# apollo1 register map
Vendor: Ambiq Micro; Series: Apollo; File version: 1.0
CPU: CM4 r1p0, little endian, MPU, FPU, 3 interrupt priority bits
Registers are 32-bit, read-write, reset 0x0 unless marked. A register's access mark holds for its fields unless they carry their own. Offsets are from the block's base; [hi:lo] are bit positions; {n}, {i} and the like mark numbered series; 'fields as' and 'values as' point back to an identical list; <NAME> marks a mode.

## ADC — Analog Digital Converter Control
Base 0x50008000
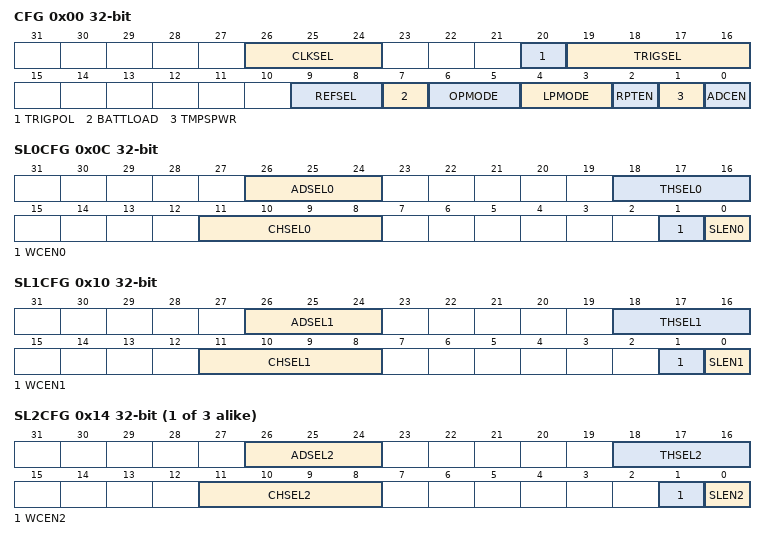
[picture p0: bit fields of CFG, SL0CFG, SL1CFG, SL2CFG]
0x00 CFG — Configuration Register
  [26:24] CLKSEL — Select the source and frequency for the ADC clock. All values not enumerated below are undefined.
    0=OFF (Low Power Mode. value.); 1=12MHZ (12 MHz ADC clock. value.); 2=6MHZ (6 MHz ADC clock. value.); 3=3MHZ (12 MHz ADC clock. value.); 4=1_5MHZ (1.5 MHz ADC clock. value.)
  [20] TRIGPOL — This bit selects the ADC trigger polarity for external off chip triggers.
    0=RISING_EDGE (Trigger on rising edge. value.); 1=FALLING_EDGE (Trigger on falling edge. value.)
  [19:16] TRIGSEL — Select the ADC trigger source.
    {v}=EXT{v} (Off chip External Trigger{v} (ADC_ET{v}) value.) (v=0..7); 8=SWT (Software Trigger value.)
  [9:8] REFSEL — Select the ADC reference voltage.
    0=INTERNAL (Internal Bandgap Reference Voltage value.); 1=VDD (Select VDD as the ADEC reference voltage. value.); 2=ADCREF (Off Chip Reference (ADC_REF) value.); 3=UNDEFINED (Reserved value.)
  [7] BATTLOAD — Control 500 Ohm battery load resistor.
    0=DIS (Disable battery load. value.); 1=EN (Enable battery load. value.)
  [6:5] OPMODE — Select the sample rate mode. It adjusts the current in the ADC for higher sample rates. A 12MHz ADC clock can result in a sample rate up to 1Msps depending on the trigger or repeating mode rate. A 1.5MHz ADC clock can result in a sample rate up 125K sps. NOTE: All other values not specified below are undefined.
    0=SAMPLE_RATE_LE_125KSPS (Sample Rate <= 125K sps value.); 2=SAMPLE_RATE_125K_1MSPS (Sample Rate 125K to 1M sps value.)
  [4:3] LPMODE — Select power mode to enter between active scans.
    0=MODE0 (Low Power Mode 0 (2'b00). Leaves the ADC fully powered between scans with no latency between a trigger event and sample data collection. value.); 1=MODE1 (Low Power Mode 1 (2'b01). Enables a low power mode for the ADC between scans requiring 50us initialization time (latency) between a trigger event and the scan (assuming the HFRC remains running and the MCU is not in deepsleep mode in which case additional startup latency for HFRC startup is required). value.); 2=MODE2 (Low Power Mode 2 (2'b10). Disconnects power and clocks to the ADC effectively eliminating all active power associated with the ADC between scans. This mode requires 150us initialization (again, assuming the HFRC remains running and the MCU is not in deepsleep mode in which case additional startup latency for HFRC startup is required). value.); 3=MODE_UNDEFINED (Undefined Mode (2'b11) value.)
  [2] RPTEN — This bit enables Repeating Scan Mode.
    0=SINGLE_SCAN (In Single Scan Mode, the ADC will complete a single scan upon each trigger event. value.); 1=REPEATING_SCAN (In Repeating Scan Mode, the ADC will complete it's first scan upon the initial trigger event and all subsequent scans will occur at regular intervals defined by the configuration programmed for the CTTMRA3 internal timer until the timer is disabled or the ADC is disabled. value.)
  [1] TMPSPWR — This enables power to the temperature sensor module. After setting this bit, the temperature sensor will remain powered down while the ADC is power is disconnected (i.e, when the ADC PWDSTAT is 2'b10).
    0=DIS (Power down the temperature sensor. value.); 1=EN (Enable the temperature sensor when the ADC is in it's active state. value.)
  [0] ADCEN — This bit enables the ADC module. While the ADC is enabled, the ADCCFG and SLOT Configuration regsiter settings must remain stable and unchanged.
    0=DIS (Disable the ADC module. value.); 1=EN (Enable the ADC module. value.)
0x04 STAT — ADC Power Status
  [1:0] PWDSTAT — Indicates the power-status of the ADC.
    0=ON (Powered on. value.); 1=SWITCH_ON_SAR_OFF (Power switch on, ADC Low Power Mode 1. value.); 2=POWER_SWITCH_OFF (Power switch off, ADC disabled. value.)
0x08 SWT — Software trigger
  [7:0] SWT — Writing 0x37 to this register generates a software trigger.
    55=GEN_SW_TRIGGER (Writing this value generates a software trigger. value.)
0x0C SL0CFG — Slot 0 Configuration Register
  [26:24] ADSEL0 — Select the number of measurements to average in the accumulate divide module for this slot.
    0=AVG_1_MSRMT (Average in 1 measurement in the accumulate divide module for this slot. value.); 1=AVG_2_MSRMTS (Average in 2 measurements in the accumulate divide module for this slot. value.); 2=AVG_4_MSRMTS (Average in 4 measurements in the accumulate divide module for this slot. value.); 3=AVG_8_MSRMT (Average in 8 measurements in the accumulate divide module for this slot. value.); 4=AVG_16_MSRMTS (Average in 16 measurements in the accumulate divide module for this slot. value.); 5=AVG_32_MSRMTS (Average in 32 measurements in the accumulate divide module for this slot. value.); 6=AVG_64_MSRMTS (Average in 64 measurements in the accumulate divide module for this slot. value.); 7=AVG_128_MSRMTS (Average in 128 measurements in the accumulate divide module for this slot. value.)
  [18:16] THSEL0 — Select the track and hold delay for this slot. NOTE: The track and hold delay must be less than 50us for correct operation. When the ADC is configured to use the 1.5Mhz clock, the track and hold delay cannot exceed 64 clocks.
    0=1_ADC_CLK (1 ADC clock cycle. value.); 1=2_ADC_CLKS (2 ADC clock cycles. value.); 2=4_ADC_CLKS (4 ADC clock cycles. value.); 3=8_ADC_CLKS (8 ADC clock cycles. value.); 4=16_ADC_CLKS (16 ADC clock cycles. value.); 5=32_ADC_CLKS (32 ADC clock cycles. value.); 6=64_ADC_CLKS (64 ADC clock cycles. value.); 7=128_ADC_CLKS (128 ADC clock cycles. value.)
  [11:8] CHSEL0 — Select one of the 13 channel inputs for this slot.
    {v}=EXT{v} (ADC_EXT{v} external GPIO pin connection. value.) (v=0..7); 8=TEMP (ADC_TEMP internal temperature sensor. value.); 9=VDD (ADC_VDD internal power rail connection. value.); 10=VSS (ADC_VSS internal ground connection. value.); 12=VBATT (ADC_VBATT internal voltage divide-by-3 connection to input power rail. value.)
  [1] WCEN0 — This bit enables the window compare function for slot 0.
    1=WCEN (Enable the window compare for slot 0. value.)
  [0] SLEN0 — This bit enables slot 0 for ADC conversions.
    1=SLEN (Enable slot 0 for ADC conversions. value.)
0x10 SL1CFG — Slot 1 Configuration Register
  [26:24] ADSEL1 — Select the number of measurements to average in the accumulate divide module for this slot.
    values as SL0CFG.ADSEL0
  [18:16] THSEL1 — Select the track and hold delay for this slot. NOTE: The track and hold delay must be less than 50us for correct operation. When the ADC is configured to use the 1.5 Mhz clock, the track and hold delay cannot exceed 64 clocks.
    values as SL0CFG.THSEL0
  [11:8] CHSEL1 — Select one of the 13 channel inputs for this slot.
    values as SL0CFG.CHSEL0
  [1] WCEN1 — This bit enables the window compare function for slot 1.
    1=WCEN (Enable the window compare for slot 1. value.)
  [0] SLEN1 — This bit enables slot 1 for ADC conversions.
    1=SLEN (Enable slot 1 for ADC conversions. value.)
{0xC+4i} SL{i}CFG (i=2..4) — Slot {i} Configuration Register
  [26:24] ADSEL{i} — Select the number of measurements to average in the accumulate divide module for this slot.
    values as SL0CFG.ADSEL0
  [18:16] THSEL{i} — Select the track and hold delay for this slot. NOTE: The track and hold delay must be less than 50us for correct operation. When the ADC is configured to use the 1.5Mhz clock, the track and hold delay cannot exceed 64 clocks.
    values as SL0CFG.THSEL0
  [11:8] CHSEL{i} — Select one of the 13 channel inputs for this slot.
    values as SL0CFG.CHSEL0
  [1] WCEN{i} — This bit enables the window compare function for slot {i}.
    1=WCEN (Enable the window compare for slot {i}. value.)
  [0] SLEN{i} — This bit enables slot {i} for ADC conversions.
    1=SLEN (Enable slot {i} for ADC conversions. value.)
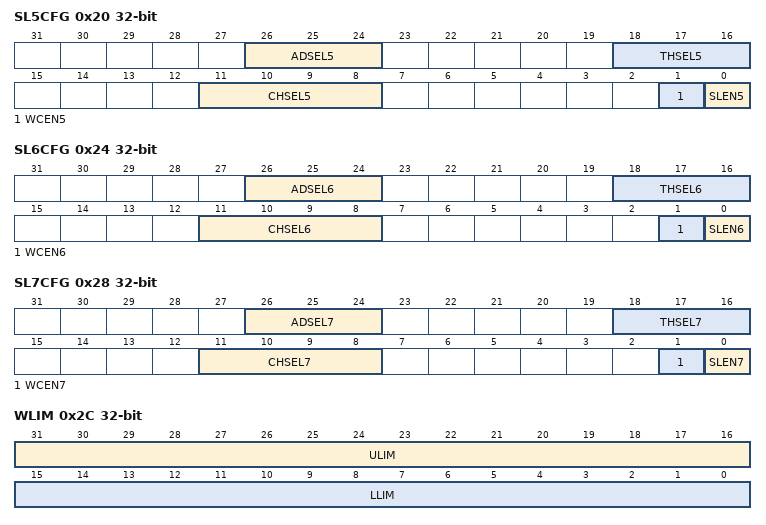
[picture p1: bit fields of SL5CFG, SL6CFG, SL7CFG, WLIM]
0x20 SL5CFG — Slot 5 Configuration Register
  [26:24] ADSEL5 — Select number of measurements to average in the accumulate divide module for this slot.
    values as SL0CFG.ADSEL0
  [18:16] THSEL5 — Select track and hold delay for this slot. NOTE: The track and hold delay must be less than 50us for correct operation. When the ADC is configured to use the 1.5Mhz clock, the track and hold delay cannot exceed 64 clocks.
    values as SL0CFG.THSEL0
  [11:8] CHSEL5 — Select one of the 13 channel inputs for this slot.
    values as SL0CFG.CHSEL0
  [1] WCEN5 — This bit enables the window compare function for slot 5.
    1=WCEN (Enable the window compare for slot 5. value.)
  [0] SLEN5 — This bit enables slot 5 for ADC conversions.
    1=SLEN (Enable slot 5 for ADC conversions. value.)
0x24 SL6CFG — Slot 6 Configuration Register
  [26:24] ADSEL6 — Select the number of measurements to average in the accumulate divide module for this slot.
    values as SL0CFG.ADSEL0
  [18:16] THSEL6 — Select track and hold delay for this slot. NOTE: The track and hold delay must be less than 50us for correct operation. When the ADC is configured to use the 1.5Mhz clock, the track and hold delay cannot exceed 64 clocks.
    values as SL0CFG.THSEL0
  [11:8] CHSEL6 — Select one of the 13 channel inputs for this slot.
    values as SL0CFG.CHSEL0
  [1] WCEN6 — This bit enables the window compare function for slot 6.
    1=WCEN (Enable the window compare for slot 6. value.)
  [0] SLEN6 — This bit enables slot 6 for ADC conversions.
    1=SLEN (Enable slot 6 for ADC conversions. value.)
0x28 SL7CFG — Slot 7 Configuration Register
  [26:24] ADSEL7 — Select the number of measurements to average in the accumulate divide module for this slot.
    values as SL0CFG.ADSEL0
  [18:16] THSEL7 — Select track and hold delay for this slot. NOTE: The track and hold delay must be less than 50us for correct operation. When the ADC is configured to use the 1.5Mhz clock, the track and hold delay cannot exceed 64 clocks.
    values as SL0CFG.THSEL0
  [11:8] CHSEL7 — Select one of the 13 channel inputs for this slot.
    values as SL0CFG.CHSEL0
  [1] WCEN7 — This bit enables the window compare function for slot 7.
    1=WCEN (Enable the window compare for slot 7. value.)
  [0] SLEN7 — This bit enables slot 7 for ADC conversions.
    1=SLEN (Enable slot 7 for ADC conversions. value.)
0x2C WLIM — Window Comparator Limits Register
  [31:16] ULIM — Sets the upper limit for the wondow comparator.
  [15:0] LLIM — Sets the lower limit for the wondow comparator.
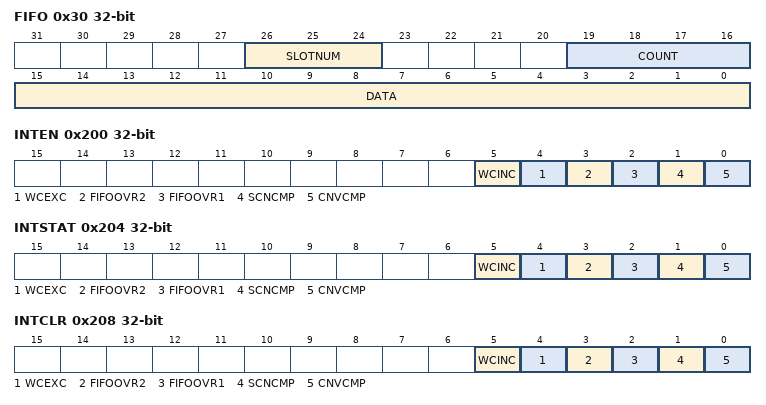
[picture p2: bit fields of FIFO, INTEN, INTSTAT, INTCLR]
0x30 FIFO — FIFO Data and Valid Count Register
  [26:24] SLOTNUM — Slot number associated with this FIFO data.
  [19:16] COUNT — Number of valid entries in the ADC FIFO.
  [15:0] DATA — Oldest data in the FIFO.
0x200 INTEN — ADC Interrupt registers: Enable
  [5] WCINC — Window comparator voltage incursion interrupt.
    1=WCINCINT (Window comparitor voltage incursion interrupt. value.)
  [4] WCEXC — Window comparator voltage excursion interrupt.
    1=WCEXCINT (Window comparitor voltage excursion interrupt. value.)
  [3] FIFOOVR2 — FIFO 100 percent full interrupt.
    1=FIFOFULLINT (FIFO 100 percent full interrupt. value.)
  [2] FIFOOVR1 — FIFO 75 percent full interrupt.
    1=FIFO75INT (FIFO 75 percent full interrupt. value.)
  [1] SCNCMP — ADC scan complete interrupt.
    1=SCNCMPINT (ADC scan complete interrupt. value.)
  [0] CNVCMP — ADC conversion complete interrupt.
    1=CNVCMPINT (ADC conversion complete interrupt. value.)
0x204 INTSTAT — ADC Interrupt registers: Status
  fields as INTEN
0x208 INTCLR — ADC Interrupt registers: Clear
  fields as INTEN
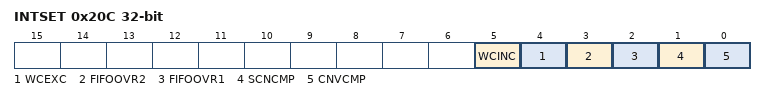
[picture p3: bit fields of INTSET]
0x20C INTSET — ADC Interrupt registers: Set
  fields as INTEN

## Notices in the file
Copyright (C) 2012-2014 ARM Limited. All rights reserved.
Purpose: System Viewer Description (SVD) Example (Schema Version 1.1)
This is a description of a none-existent and incomplete device
for demonstration purposes only.
Redistribution and use in source and binary forms, with or without
modification, are permitted provided that the following conditions are met:
- Redistributions of source code must retain the above copyright
notice, this list of conditions and the following disclaimer.
- Redistributions in binary form must reproduce the above copyright
notice, this list of conditions and the following disclaimer in the
documentation and/or other materials provided with the distribution.
- Neither the name of ARM nor the names of its contributors may be used
to endorse or promote products derived from this software without
specific prior written permission.
THIS SOFTWARE IS PROVIDED BY THE COPYRIGHT HOLDERS AND CONTRIBUTORS "AS IS"
AND ANY EXPRESS OR IMPLIED WARRANTIES, INCLUDING, BUT NOT LIMITED TO, THE
IMPLIED WARRANTIES OF MERCHANTABILITY AND FITNESS FOR A PARTICULAR PURPOSE
ARE DISCLAIMED. IN NO EVENT SHALL COPYRIGHT HOLDERS AND CONTRIBUTORS BE
LIABLE FOR ANY DIRECT, INDIRECT, INCIDENTAL, SPECIAL, EXEMPLARY, OR
CONSEQUENTIAL DAMAGES (INCLUDING, BUT NOT LIMITED TO, PROCUREMENT OF
SUBSTITUTE GOODS OR SERVICES; LOSS OF USE, DATA, OR PROFITS; OR BUSINESS
INTERRUPTION) HOWEVER CAUSED AND ON ANY THEORY OF LIABILITY, WHETHER IN
CONTRACT, STRICT LIABILITY, OR TORT (INCLUDING NEGLIGENCE OR OTHERWISE)
ARISING IN ANY WAY OUT OF THE USE OF THIS SOFTWARE, EVEN IF ADVISED OF THE
POSSIBILITY OF SUCH DAMAGE.
